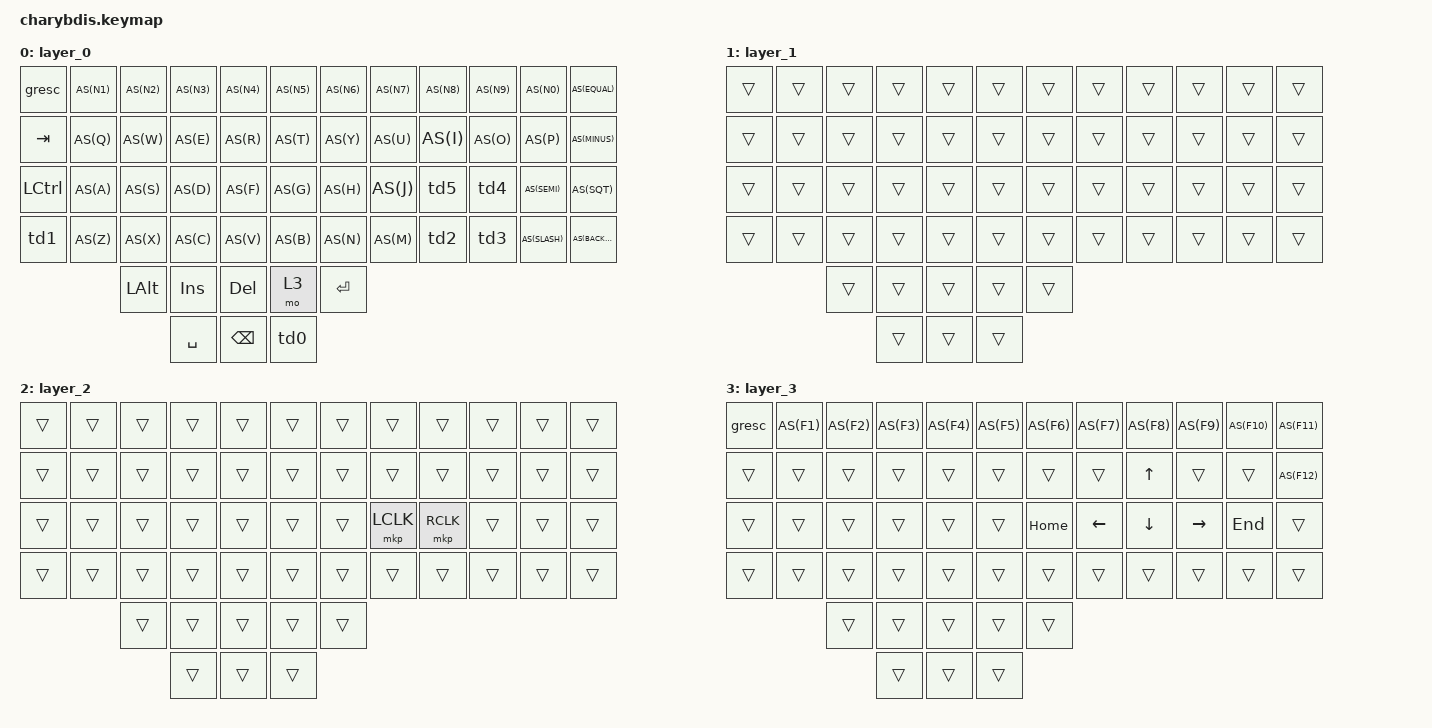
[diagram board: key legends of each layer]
#include <dt-bindings/zmk/mouse.h>
#include <behaviors.dtsi>
#include <dt-bindings/zmk/bt.h>
#include <dt-bindings/zmk/keys.h>
#include <dt-bindings/zmk/pointing.h>
#define CHARYBDIS_AUTO_POINTER_LAYER_TRIGGER_ENABLE
#define CHARYBDIS_AUTO_POINTER_LAYER_TRIGGER_TIMEOUT_MS 1000
#define AS(keycode) &as LS(keycode) keycode
&lt {
    tapping-term-ms = <200>;
    flavor = "balanced";
    quick-tap-ms = <150>;
};

&mt {
    tapping-term-ms = <200>; // This is the value already set by default
};

/ {
    behaviors {
        as: auto_shift {
            compatible = "zmk,behavior-hold-tap";
            label = "AUTO_SHIFT";
            #binding-cells = <2>;
            tapping_term_ms = <200>;
            quick_tap_ms = <0>;
            flavor = "tap-preferred";
            bindings = <&kp>, <&kp>;
        };
        
        td0: tap_dance_0 {
            compatible = "zmk,behavior-tap-dance";
            label = "TAP_DANCE_0";
            #binding-cells = <0>;
            tapping-term-ms = <150>;
            bindings = <&mkp LCLK>, <&mkp RCLK>;
        };
        
        td1: tap_dance_1 {
            compatible = "zmk,behavior-tap-dance";
            label = "TAP_DANCE_1";
            #binding-cells = <0>;
            tapping-term-ms = <200>;
            bindings = <&kp LEFT_SHIFT>, <&kp LWIN>;
        };
        
        td2: tap_dance_2 {
            compatible = "zmk,behavior-tap-dance";
            label = "TAP_DANCE_2";
            #binding-cells = <0>;
            tapping-term-ms = <200>;
            bindings = <AS(COMMA)>, <AS(LEFT_BRACKET)>;
        };
        
        td3: tap_dance_3 {
            compatible = "zmk,behavior-tap-dance";
            label = "TAP_DANCE_3";
            #binding-cells = <0>;
            tapping-term-ms = <200>;
            bindings = <AS(PERIOD)>, <AS(RIGHT_BRACKET)>;
        };
        
        td4: tap_dance_4 {
            compatible = "zmk,behavior-tap-dance";
            label = "TAP_DANCE_4";
            #binding-cells = <0>;
            tapping-term-ms = <200>;
            bindings = <AS(L)>, <&mo 2>;
        };
        
        td5: tap_dance_5 {
            compatible = "zmk,behavior-tap-dance";
            label = "TAP_DANCE_5";
            #binding-cells = <0>;
            tapping-term-ms = <200>;
            bindings = <AS(K)>, <&mo 1>;
        };
    };

    keymap {
        compatible = "zmk,keymap";

        layer_0 {
            bindings = <
&gresc          AS(N1)          AS(N2)          AS(N3)                  AS(N4)              AS(N5)              AS(N6)              AS(N7)              AS(N8)              AS(N9)                      AS(N0)              AS(EQUAL)
&kp TAB         AS(Q)           AS(W)           AS(E)                   AS(R)               AS(T)               AS(Y)               AS(U)               AS(I)               AS(O)                       AS(P)               AS(MINUS)
&kp LCTRL       AS(A)           AS(S)           AS(D)                   AS(F)               AS(G)               AS(H)               AS(J)               &td5               &td4                       AS(SEMI)            AS(SQT)
&td1            AS(Z)           AS(X)           AS(C)                   AS(V)               AS(B)               AS(N)               AS(M)               &td2                &td3                  AS(SLASH)           AS(BACKSLASH)
                                &kp LALT  &kp INSERT  &kp DELETE       &mo 3   &kp ENTER
                                          &kp SPACE   &kp BACKSPACE    &td0
            >;
            trackball-bindings = <&tmv_coarse>;
        };

        layer_1 {
            bindings = <
&trans  &trans   &trans    &trans   &trans         &trans         &trans         &trans         &trans     &trans  &trans   &trans
&trans  &trans   &trans    &trans   &trans         &trans         &trans         &trans          &trans     &trans  &trans   &trans
&trans  &trans   &trans    &trans   &trans         &trans         &trans         &trans     &trans          &trans  &trans   &trans
&trans  &trans   &trans    &trans   &trans       &trans    &trans            &trans         &trans          &trans  &trans   &trans
                                   &trans         &trans         &trans         &trans         &trans
                                                 &trans         &trans         &trans
            >;
            trackball-bindings = <&tsl>;
        };

       layer_2 {
            bindings = <
&trans        &trans         &trans         &trans      &trans      &trans         &trans       &trans      &trans       &trans         &trans         &trans
&trans        &trans        &trans        &trans         &trans      &trans      &trans          &trans      &trans       &trans         &trans      &trans
&trans        &trans        &trans        &trans         &trans     &trans         &trans         &mkp LCLK     &mkp RCLK        &trans        &trans        &trans
&trans       &trans        &trans        &trans         &trans      &trans         &trans       &trans      &trans       &trans         &trans        &trans
                                         &trans         &trans      &trans     &trans       &trans
                                                       &trans      &trans        &trans
            >;
            trackball-bindings = <&tmv_coarse>;
        };
        layer_3 {
            bindings = <
&gresc          AS(F1)          AS(F2)      AS(F3)      AS(F4)          AS(F5)          AS(F6)       AS(F7)         AS(F8)      AS(F9)      AS(F10)     AS(F11)
&trans          &trans      &trans      &trans          &trans          &trans          &trans       &trans         &kp UP      &trans      &trans      AS(F12) 
&trans          &trans      &trans      &trans          &trans          &trans          &kp HOME     &kp LEFT       &kp DOWN    &kp RIGHT   &kp END     &trans 
&trans          &trans      &trans      &trans          &trans          &trans          &trans       &trans         &trans      &trans      &trans      &trans
                                &trans   &trans   &trans                &trans          &trans 
                                              &trans    &trans          &trans 
            >;
            trackball-bindings = <&tmv_coarse>;
       };
       /*  layer_4 {
            bindings = <
&trans  &trans  &trans     &trans     &trans     &trans       &trans     &trans     &trans     &trans     &trans  &trans
&trans  &trans  &trans     &trans     &trans     &trans       &trans     &trans     &trans     &trans     &trans  &trans
&trans  &trans  &trans     &mkp MCLK  &trans     &trans       &trans     &trans     &mkp MCLK  &trans     &trans  &trans
&trans  &trans  &mkp RCLK  &trans     &mkp LCLK  &trans       &trans     &mkp LCLK  &trans     &mkp RCLK  &trans  &trans
                           &trans     &mkp LCLK  &mkp RCLK    &mkp RCLK  &mkp LCLK
                                      &trans     &trans       &trans
            >;
                
                
                trackball-bindings = <&tsl>;
        };

        layer_5 {
            bindings = <
&trans  &trans  &trans     &trans     &trans     &trans       &trans     &trans     &trans     &trans     &trans  &trans
&trans  &trans  &trans     &trans     &trans     &trans       &trans     &trans     &trans     &trans     &trans  &trans
&trans  &trans  &trans     &mkp MCLK  &trans     &trans       &trans     &trans     &mkp MCLK  &trans     &trans  &trans
&trans  &trans  &mkp RCLK  &trans     &mkp LCLK  &trans       &trans     &mkp LCLK  &trans     &mkp RCLK  &trans  &trans
                           &trans     &mkp LCLK  &mkp RCLK    &mkp RCLK  &mkp LCLK
                                      &trans     &trans       &trans
            >;
                trackball-bindings = <&tmv_fine>;
                
        };*/
    };
};
